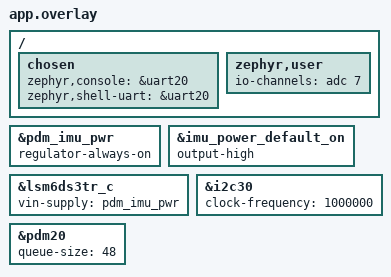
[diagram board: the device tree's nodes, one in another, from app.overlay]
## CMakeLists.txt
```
# SPDX-License-Identifier: Apache-2.0

cmake_minimum_required(VERSION 3.20.0)

set(DTC_OVERLAY_FILE ${CMAKE_CURRENT_SOURCE_DIR}/app.overlay CACHE STRING "" FORCE)

find_package(Zephyr REQUIRED HINTS $ENV{ZEPHYR_BASE})
project(openfloat-serial)

target_sources(app PRIVATE src/main.c src/trace_buffer.c src/trace_store.c src/shot_log.c src/sleep_flush.c src/settings_read.c src/boot_restore.c src/settings_retry.c src/shot_recovery.c)
# The pinned SDK header defines existing Settings/ZMS IDs. Strict boot reads
# preserve errors hidden by the SDK's bulk and single-key Settings loaders.
target_include_directories(app PRIVATE ${ZEPHYR_BASE}/subsys/settings/include)
# Reject undefined shifts, including narrow literals in 128-bit UUID encoders.
target_compile_options(app PRIVATE -Werror=shift-count-overflow)
target_link_libraries(app PRIVATE m)
```

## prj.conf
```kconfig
# Battery-safe default: the XIAO nRF54L15 v1.0 can fail to boot from battery
# when the UART console is enabled. Use prj_uart.conf as an overlay when USB
# serial logs are needed for bench debugging.
CONFIG_SERIAL=n
CONFIG_PRINTK=n
CONFIG_CONSOLE=n
CONFIG_UART_CONSOLE=n
CONFIG_STDOUT_CONSOLE=n
CONFIG_I2C=y
CONFIG_GPIO=y
CONFIG_REGULATOR=y
CONFIG_REGULATOR_FIXED=y
CONFIG_CPU_LOAD=y
CONFIG_ADC=y


# Persistent shot counter: Zephyr Settings on the nRF54L RRAM via ZMS (the
# byte-alterable storage backend for this SoC; Partition Manager allocates the
# settings_storage partition automatically when SETTINGS is enabled).
CONFIG_FLASH=y
CONFIG_FLASH_MAP=y
CONFIG_ZMS=y
# Live acknowledgments save the canonical empty queue; avoid rewriting it.
CONFIG_ZMS_NO_DOUBLE_WRITE=y
CONFIG_SETTINGS=y
CONFIG_SETTINGS_ZMS=y

CONFIG_MAIN_STACK_SIZE=16384
CONFIG_SYSTEM_WORKQUEUE_STACK_SIZE=4096
CONFIG_MPSL_WORK_STACK_SIZE=4096
CONFIG_BT=y
CONFIG_BT_PERIPHERAL=y
CONFIG_BT_DATA_LEN_UPDATE=y
CONFIG_BT_USER_DATA_LEN_UPDATE=y
CONFIG_BT_PHY_UPDATE=y
CONFIG_BT_USER_PHY_UPDATE=y
CONFIG_BT_DEVICE_NAME="OpenFloat-463F"
CONFIG_BT_DEVICE_APPEARANCE=833
CONFIG_BT_CTLR_TX_PWR_PLUS_8=y
CONFIG_BT_MAX_CONN=1
CONFIG_BT_PERIPHERAL_PREF_MIN_INT=6
CONFIG_BT_PERIPHERAL_PREF_MAX_INT=6
CONFIG_BT_PERIPHERAL_PREF_LATENCY=0
CONFIG_BT_PERIPHERAL_PREF_TIMEOUT=400
CONFIG_BT_RX_STACK_SIZE=4096
CONFIG_BT_HCI_TX_STACK_SIZE=2048
CONFIG_BT_LONG_WQ_STACK_SIZE=4096
CONFIG_BT_BUF_CMD_TX_COUNT=2
CONFIG_BT_BUF_ACL_TX_COUNT=6
CONFIG_BT_BUF_ACL_TX_SIZE=217
CONFIG_BT_L2CAP_TX_BUF_COUNT=6
CONFIG_BT_BUF_ACL_RX_SIZE=217
CONFIG_BT_L2CAP_TX_MTU=212

# Deep Sleep / Power Management
CONFIG_POWEROFF=y
CONFIG_REBOOT=y

# Keep 64 KB for ordinary settings, the compact shot log, and four chunked traces.
CONFIG_PM_PARTITION_SIZE_SETTINGS_STORAGE=0x10000

# Audio and PDM microphone drivers
CONFIG_AUDIO=y
CONFIG_AUDIO_DMIC=y
```

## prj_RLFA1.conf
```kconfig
CONFIG_BT_DEVICE_NAME="OpenFloat-RLFA1"
```

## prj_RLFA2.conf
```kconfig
CONFIG_BT_DEVICE_NAME="OpenFloat-RLFA2"
```

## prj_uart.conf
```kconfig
# USB bench/debug overlay. Build with:
#   west build ... -DOVERLAY_CONFIG=prj_uart.conf
#
# Keep the default prj.conf battery-safe for standalone use.
CONFIG_SERIAL=y
CONFIG_PRINTK=y
CONFIG_CONSOLE=y
CONFIG_UART_CONSOLE=y
CONFIG_STDOUT_CONSOLE=y
```

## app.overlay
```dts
&pdm_imu_pwr {
	regulator-always-on;
};

&imu_power_default_on {
	output-high;
};

&lsm6ds3tr_c {
	vin-supply = <&pdm_imu_pwr>;
};

&i2c30 {
	clock-frequency = <1000000>;
};

&pdm20 {
	/* 14-sample blocks arrive at ~1143/s; default queue-size=4 starves PDM. */
	queue-size = <48>;
};

/ {
	chosen {
		zephyr,console = &uart20;
		zephyr,shell-uart = &uart20;
	};

	zephyr,user {
		io-channels = <&adc 7>;
	};
};
```

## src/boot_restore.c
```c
/* SPDX-License-Identifier: Apache-2.0 */
#include "boot_restore.h"
#include <errno.h>
#include <stdio.h>

int boot_restore(const struct boot_restore_io *io)
{
	static const char *const keys[] = {
		"shots", "shotlog", "wakesens", "sleeptime", "sleepsens", "bufrate",
		"bufnvs", "autosleep", "streamrate", "followms", "cant_offset", "pitch_offset",
	};
	int result = 0;
	for (unsigned int attempt = 0; attempt < BOOT_RESTORE_ATTEMPTS; attempt++) {
		result = io->initialize(io->context);
		if (!result) {
			io->reset(io->context);
			for (unsigned int i = 0; i < sizeof(keys) / sizeof(keys[0]); i++) {
				int rc = io->restore_setting(io->context, keys[i]);
				if (i >= 2 && (rc == -EBADMSG || rc == -EMSGSIZE)) continue;
				if (rc && !result) result = rc;
			}
			for (unsigned int slot = 0; slot < 10; slot++) {
				char key[4];
				snprintf(key, sizeof(key), "t%u", slot);
				int rc = io->restore_setting(io->context, key);
				if (rc == -EBADMSG || rc == -EMSGSIZE) continue;
				if (rc && !result) result = rc;
			}
			int rc = io->restore_traces(io->context);
			if (rc && !result) result = rc;
		}
		if (!result) result = io->commit_recovered(io->context);
		if (!result) return 0;
		if (attempt + 1 < BOOT_RESTORE_ATTEMPTS) io->retry_delay(io->context, BOOT_RESTORE_RETRY_DELAY_MS);
	}
	return result;
}
```

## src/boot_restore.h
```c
/* SPDX-License-Identifier: Apache-2.0 */
#ifndef OPENFLOAT_BOOT_RESTORE_H
#define OPENFLOAT_BOOT_RESTORE_H

#include <stdint.h>

#define BOOT_RESTORE_ATTEMPTS 3
#define BOOT_RESTORE_RETRY_DELAY_MS 1000

struct boot_restore_io {
	void *context;
	int (*initialize)(void *context);
	/* Reset RAM to startup defaults, including any partial prior restoration. */
	void (*reset)(void *context);
	/* Relative OpenFloat key. Zero means applied or absent; -EBADMSG/-EMSGSIZE
	 * means malformed. Other errors must propagate without being called absent. */
	int (*restore_setting)(void *context, const char *key);
	int (*restore_traces)(void *context);
	/* Called only after every read/restore succeeds. Persist a recovered capture
	 * ID before BLE acknowledgments can delete the records that established it.
	 * Fresh defaults and unchanged counters need no application writes. */
	int (*commit_recovered)(void *context);
	void (*retry_delay)(void *context, uint32_t milliseconds);
};

/* Run before BLE, acquisition, or application persistence. Malformed counters
 * or shot queues prevent startup; malformed tuning/legacy traces retain defaults.
 * A failure after three passes means the caller must keep startup closed and
 * may retry later. commit_recovered cannot run after any failed read/restore.
 */
int boot_restore(const struct boot_restore_io *io);

#endif
```

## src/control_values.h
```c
/* SPDX-License-Identifier: Apache-2.0 */
#ifndef OPENFLOAT_CONTROL_VALUES_H
#define OPENFLOAT_CONTROL_VALUES_H

#include <errno.h>
#include <math.h>
#include <stdbool.h>
#include <stdint.h>
#include <stdlib.h>
#include <string.h>

/* Parse the complete value before changing device state. strtoul alone accepts
 * negative IDs on the 32-bit target, while atoi treats malformed toggles as 0.
 * Failed conversions leave the caller's value unchanged.
 */
static inline bool openfloat_parse_u32(const char *text, uint32_t *value)
{
	if (*text < '0' || *text > '9') return false;
	char *end;
	errno = 0;
	unsigned long parsed = strtoul(text, &end, 10);
	if (errno || *end || parsed > UINT32_MAX) return false;
	*value = (uint32_t)parsed;
	return true;
}

/* Signed decimal values retain the documented lower/upper clamps for timeout
 * and follow-through commands. Whitespace, suffixes, and overflow are errors.
 */
static inline bool openfloat_parse_i32(const char *text, int32_t *value)
{
	const char *digits = text;
	if (*digits == '-' || *digits == '+') digits++;
	if (*digits < '0' || *digits > '9') return false;
	char *end;
	errno = 0;
	long parsed = strtol(text, &end, 10);
	if (errno || *end || parsed < INT32_MIN || parsed > INT32_MAX) return false;
	*value = (int32_t)parsed;
	return true;
}

/* Accept decimal fractions and exponents, but never NaN, infinity, hexadecimal
 * notation, whitespace, or a partially parsed value. Range errors are rejected
 * before a clamp or float-to-integer conversion can run.
 */
static inline bool openfloat_parse_float(const char *text, float *value)
{
	for (const char *p = text; *p; p++) {
		if ((*p < '0' || *p > '9') && *p != '.' && *p != 'e' && *p != 'E' &&
		    *p != '+' && *p != '-') return false;
	}
	char *end;
	errno = 0;
	float parsed = strtof(text, &end);
	if (errno || end == text || *end || !isfinite(parsed)) return false;
	*value = parsed;
	return true;
}

static inline bool openfloat_valid_buffer_rate(uint32_t value)
{
	return value == 0 || value == 52 || value == 104 || value == 208;
}

static inline bool openfloat_valid_stream_divider(uint32_t value)
{
	return value == 1 || value == 2 || value == 5 || value == 10 || value == 20;
}

/* Persisted values use milli-g and milliseconds. Reject corrupt or older
 * invalid values on restore so the initialized defaults remain in effect.
 */
static inline bool openfloat_valid_tuning_setting(const char *name, uint32_t value)
{
	if (!strcmp(name, "wakesens")) return value >= 500 && value <= 8000;
	if (!strcmp(name, "sleeptime")) return value >= 5000 && value <= 600000;
	if (!strcmp(name, "sleepsens")) return value >= 50 && value <= 500;
	if (!strcmp(name, "bufrate")) return openfloat_valid_buffer_rate(value);
	if (!strcmp(name, "bufnvs") || !strcmp(name, "autosleep")) return value <= 1;
	if (!strcmp(name, "streamrate")) return openfloat_valid_stream_divider(value);
	if (!strcmp(name, "followms")) return value <= 3000;
	return false;
}

#endif
```

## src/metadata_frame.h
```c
/* SPDX-License-Identifier: Apache-2.0 */
#ifndef OPENFLOAT_METADATA_FRAME_H
#define OPENFLOAT_METADATA_FRAME_H

#include <stdint.h>

/* Type 2/3 v2: retain the 29-byte envelope and release sequence at 26.
 * Former reserved timing words at 22/24 carry the upper counter halves.
 */
static inline void openfloat_write_shot_counters(uint8_t frame[29],
					       uint32_t count, uint32_t shot_id)
{
	frame[2] = 2;
	frame[4] = (uint8_t)count;
	frame[5] = (uint8_t)(count >> 8);
	frame[6] = (uint8_t)shot_id;
	frame[7] = (uint8_t)(shot_id >> 8);
	frame[22] = (uint8_t)(shot_id >> 16);
	frame[23] = (uint8_t)(shot_id >> 24);
	frame[24] = (uint8_t)(count >> 16);
	frame[25] = (uint8_t)(count >> 24);
}

/* Type 5 v2: the former reserved word at 18 extends the lifetime count. */
static inline void openfloat_write_storage_count(uint8_t frame[29], uint32_t count)
{
	frame[2] = 2;
	frame[4] = (uint8_t)count;
	frame[5] = (uint8_t)(count >> 8);
	frame[18] = (uint8_t)(count >> 16);
	frame[19] = (uint8_t)(count >> 24);
}

#endif
```

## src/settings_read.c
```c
/* SPDX-License-Identifier: Apache-2.0 */
#include "settings_read.h"
#include <errno.h>
#include <string.h>
#include <zephyr/sys/hash_function.h>
#include "settings/settings_zms.h"

#if !defined(CONFIG_SETTINGS_ZMS) || defined(CONFIG_SETTINGS_ZMS_LEGACY)
#error "Strict Settings reads require the configured non-legacy ZMS backend"
#endif

int openfloat_settings_read(struct zms_fs *fs, const char *key, void *data, size_t capacity)
{
	if (!fs || !fs->ready) return -EACCES;
	size_t length = strlen(key);
	if (!length || length >= SETTINGS_FULL_NAME_LEN) return -EINVAL;
	uint32_t hash = sys_hash32(key, length) & ZMS_HASH_MASK;
	for (unsigned int collision = 0; collision <= ZMS_MAX_COLLISIONS; collision++) {
		uint32_t name_id = ZMS_NAME_ID_FROM_HASH(ZMS_UPDATE_COLLISION_NUM(hash, collision));
		ssize_t rc = zms_get_data_length(fs, name_id);
		if (rc == -ENOENT) continue;
		if (rc < 0) return (int)rc;
		if ((size_t)rc != length) continue;
		char name[SETTINGS_FULL_NAME_LEN];
		rc = zms_read(fs, name_id, name, length);
		if (rc < 0) return (int)rc;
		if ((size_t)rc != length) return -EBADMSG;
		if (memcmp(name, key, length)) continue;
		uint32_t value_id = ZMS_DATA_ID_FROM_NAME(name_id);
		rc = zms_get_data_length(fs, value_id);
		if (rc == -ENOENT || rc == 0) return -EBADMSG;
		if (rc < 0) return (int)rc;
		if ((size_t)rc > capacity) return -EMSGSIZE;
		size_t size = (size_t)rc;
		rc = zms_read(fs, value_id, data, size);
		return rc < 0 ? (int)rc : ((size_t)rc == size ? (int)rc : -EBADMSG);
	}
	return 0;
}
```

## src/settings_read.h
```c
/* SPDX-License-Identifier: Apache-2.0 */
#ifndef OPENFLOAT_SETTINGS_READ_H
#define OPENFLOAT_SETTINGS_READ_H

#include <stddef.h>
struct zms_fs;

/* Boot-only read of an existing Settings/ZMS key. Unlike the SDK's name lookup,
 * preserve storage errors instead of treating them as absent settings. Returns
 * the exact value length, zero for a missing key, or a negative error. A name
 * whose value is missing is malformed, rather than a fresh-device default.
 * Oversized values return -EMSGSIZE without reading into the destination.
 * The caller initializes Settings and serializes against all Settings writers.
 */
int openfloat_settings_read(struct zms_fs *fs, const char *key, void *data, size_t capacity);

#endif
```

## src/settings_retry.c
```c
/* SPDX-License-Identifier: Apache-2.0 */
#include "settings_retry.h"
#include "sleep_flush.h"

void settings_retry_request(struct settings_retry *queue, uint32_t mask, uint32_t now_ms)
{
	mask &= SETTINGS_ALL;
	queue->pending_mask |= mask;
	queue->failed_mask &= ~mask;
	for (unsigned int key = 0; key < SETTING_COUNT; key++) {
		if (!(mask & (UINT32_C(1) << key))) continue;
		queue->token[key]++;
		queue->attempts[key] = 0;
		queue->due_ms[key] = now_ms;
	}
}

int settings_retry_take(struct settings_retry *queue, uint32_t now_ms, uint32_t *token)
{
	for (unsigned int i = 0; i < SETTING_COUNT; i++) {
		unsigned int key = (queue->next_key + i) % SETTING_COUNT;
		uint32_t bit = UINT32_C(1) << key;
		if (!(queue->pending_mask & bit) || (int32_t)(now_ms - queue->due_ms[key]) < 0) continue;
		queue->pending_mask &= ~bit;
		queue->attempts[key]++;
		queue->next_key = (key + 1) % SETTING_COUNT;
		*token = queue->token[key];
		return (int)key;
	}
	return -1;
}

void settings_retry_finish(struct settings_retry *queue, enum openfloat_setting key,
			   uint32_t token, int result, uint32_t now_ms)
{
	if (queue->token[key] != token) return;
	uint32_t bit = UINT32_C(1) << key;
	if (!result) {
		queue->failed_mask &= ~bit;
	} else {
		queue->failed_mask |= bit;
		if (queue->attempts[key] < SETTINGS_RETRY_ATTEMPTS) {
			queue->pending_mask |= bit;
			queue->due_ms[key] = now_ms + SETTINGS_RETRY_DELAY_MS;
		}
	}
}

uint32_t settings_retry_delay(const struct settings_retry *queue, uint32_t now_ms)
{
	uint32_t delay = UINT32_MAX;
	for (unsigned int key = 0; key < SETTING_COUNT; key++) {
		if (!(queue->pending_mask & (UINT32_C(1) << key))) continue;
		int32_t remaining = (int32_t)(queue->due_ms[key] - now_ms);
		if (remaining <= 0) return 0;
		if ((uint32_t)remaining < delay) delay = (uint32_t)remaining;
	}
	return delay;
}

void settings_retry_settle(struct settings_retry *queue, enum openfloat_setting key, int result)
{
	uint32_t bit = UINT32_C(1) << key;
	queue->pending_mask &= ~bit;
	if (result) queue->failed_mask |= bit;
	else queue->failed_mask &= ~bit;
}

const char *settings_retry_key(enum openfloat_setting key)
{
	static const char *const names[] = {
		"openfloat/shots", "openfloat/shotlog", "openfloat/wakesens", "openfloat/sleeptime",
		"openfloat/sleepsens", "openfloat/bufrate", "openfloat/bufnvs", "openfloat/autosleep",
		"openfloat/streamrate", "openfloat/followms", "openfloat/cant_offset", "openfloat/pitch_offset",
	};
	_Static_assert(sizeof(names) / sizeof(names[0]) == SETTING_COUNT, "Settings key list changed");
	return names[key];
}

int settings_retry_save(enum openfloat_setting key, const struct sleep_flush_values *values,
			int (*write)(void *context, const char *key, const void *data, size_t size), void *context)
{
	const void *const data[] = {
		&values->counters, values->queue, &values->wakesens, &values->sleeptime,
		&values->sleepsens, &values->bufrate, &values->bufnvs, &values->autosleep,
		&values->streamrate, &values->followms, &values->cant_offset, &values->pitch_offset,
	};
	_Static_assert(sizeof(data) / sizeof(data[0]) == SETTING_COUNT, "Settings value list changed");
	size_t size = key == SETTING_SHOTS ? sizeof(values->counters) :
		(key == SETTING_SHOTLOG ? sizeof(*values->queue) : sizeof(uint32_t));
	return write(context, settings_retry_key(key), data[key], size);
}
```

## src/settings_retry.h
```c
/* SPDX-License-Identifier: Apache-2.0 */
#ifndef OPENFLOAT_SETTINGS_RETRY_H
#define OPENFLOAT_SETTINGS_RETRY_H

#include <stddef.h>
#include <stdint.h>

enum openfloat_setting {
	SETTING_SHOTS, SETTING_SHOTLOG, SETTING_WAKESENS, SETTING_SLEEPTIME,
	SETTING_SLEEPSENS, SETTING_BUFRATE, SETTING_BUFNVS, SETTING_AUTOSLEEP,
	SETTING_STREAMRATE, SETTING_FOLLOWMS, SETTING_CANT_OFFSET, SETTING_PITCH_OFFSET,
	SETTING_COUNT,
};
#define SETTINGS_ALL ((UINT32_C(1) << SETTING_COUNT) - 1)
#define SETTINGS_RETRY_DELAY_MS 1000
#define SETTINGS_RETRY_ATTEMPTS 3

/* Caller serializes queue operations. Each new value gets a fresh token and
 * budget; obsolete I/O results cannot clear/retry its replacement. Deadlines
 * use wrapping milliseconds, with intervals always below INT32_MAX.
 */
struct settings_retry {
	uint32_t pending_mask, failed_mask;
	uint32_t token[SETTING_COUNT], due_ms[SETTING_COUNT];
	uint8_t attempts[SETTING_COUNT], next_key;
};

void settings_retry_request(struct settings_retry *queue, uint32_t mask, uint32_t now_ms);
/* Returns a ready key or -1. Ready keys rotate so one busy key cannot starve
 * the others. Failed keys wait their own deadline even after unrelated updates.
 */
int settings_retry_take(struct settings_retry *queue, uint32_t now_ms, uint32_t *token);
void settings_retry_finish(struct settings_retry *queue, enum openfloat_setting key,
			   uint32_t token, int result, uint32_t now_ms);
/* Zero if some key is ready, UINT32_MAX if none are pending, else next delay. */
uint32_t settings_retry_delay(const struct settings_retry *queue, uint32_t now_ms);
/* Only after sealing updates and draining I/O: account for a final sleep write.
 * A failed final batch remains unsaved without starting another immediate loop.
 */
void settings_retry_settle(struct settings_retry *queue, enum openfloat_setting key, int result);

const char *settings_retry_key(enum openfloat_setting key);
struct sleep_flush_values;
/* The existing twelve Settings layouts, shared by ordinary saves and sleep. */
int settings_retry_save(enum openfloat_setting key, const struct sleep_flush_values *values,
			int (*write)(void *context, const char *key, const void *data, size_t size), void *context);

#endif
```

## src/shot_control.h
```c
/* SPDX-License-Identifier: Apache-2.0 */
#ifndef OPENFLOAT_SHOT_CONTROL_H
#define OPENFLOAT_SHOT_CONTROL_H

#include <stdbool.h>
#include <stdint.h>
#include <string.h>

struct openfloat_shot_counters {
	uint32_t count;
	uint32_t shot_id;
};

_Static_assert(sizeof(struct openfloat_shot_counters) == 8, "Shot counter settings layout changed");

/* Existing four-byte settings used the lifetime count as the capture ID. New
 * settings save both fields in one value so corrections cannot rewind IDs on
 * reboot. Invalid layouts leave the current counters unchanged.
 */
static inline bool openfloat_restore_shot_counters(struct openfloat_shot_counters *counters,
						  const uint8_t *bytes, size_t size)
{
	if (size != sizeof(uint32_t) && size != sizeof(*counters)) return false;
	struct openfloat_shot_counters restored;
	memcpy(&restored.count, bytes, sizeof(restored.count));
	if (size == sizeof(uint32_t)) restored.shot_id = restored.count;
	else memcpy(&restored.shot_id, bytes + sizeof(restored.count), sizeof(restored.shot_id));
	*counters = restored;
	return true;
}

static inline void openfloat_set_shot_count(struct openfloat_shot_counters *counters, uint32_t count)
{
	counters->count = count;
}

/* Count corrections and resets preserve IDs. The lifetime count saturates at
 * its limit, while capture IDs retain their existing unsigned wrap behavior.
 */
static inline void openfloat_advance_shot(struct openfloat_shot_counters *counters)
{
	if (counters->count < UINT32_MAX) counters->count++;
	counters->shot_id++;
}

#endif
```

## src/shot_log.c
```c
/* SPDX-License-Identifier: Apache-2.0 */
#include "shot_log.h"
#include <string.h>

static uint16_t read16(const uint8_t *p)
{
	return (uint16_t)p[0] | ((uint16_t)p[1] << 8);
}

static uint32_t read32(const uint8_t *p)
{
	return read16(p) | ((uint32_t)read16(p + 2) << 16);
}

static void write16(uint8_t *p, uint16_t value)
{
	p[0] = (uint8_t)value;
	p[1] = (uint8_t)(value >> 8);
}

bool shot_log_valid_storage_size(size_t size)
{
	return size == sizeof(struct stored_shot_log) || size == SHOT_LOG_LEGACY_TIMED_SIZE ||
		size == SHOT_LOG_LEGACY_SIZE;
}

bool shot_log_restore(struct stored_shot_log *dest, const uint8_t *bytes,
		      size_t size, size_t bytes_read)
{
	if (!shot_log_valid_storage_size(size) || bytes_read != size) return false;
	uint16_t count = read16(bytes);
	if (count > STORED_SHOT_CAPACITY) return false;
	bool current = size == sizeof(*dest);
	size_t stride = current ? sizeof(struct stored_shot) :
		(size == SHOT_LOG_LEGACY_TIMED_SIZE ? 22 : 18);
	size_t values = current ? 8 : 4;
	/* Length and count are checked before any mutation. All three formats are
	 * little-endian, so no packed or potentially unaligned struct casts are used.
	 */
	struct stored_shot_log restored;
	memset(&restored, 0, sizeof(restored));
	restored.count = count;
	for (uint16_t i = 0; i < count; i++) {
		const uint8_t *p = bytes + (current ? 4 : 2) + i * stride;
		struct stored_shot *shot = &restored.shots[i];
		shot->shot_count = read16(p);
		shot->shot_id = current ? read32(p + 4) : read16(p + 2);
		shot->ax_mg = (int16_t)read16(p + values);
		shot->ay_mg = (int16_t)read16(p + values + 2);
		shot->az_mg = (int16_t)read16(p + values + 4);
		shot->threshold_cg = read16(p + values + 6);
		shot->roll_cdeg = (int16_t)read16(p + values + 8);
		shot->pitch_cdeg = (int16_t)read16(p + values + 10);
		shot->yaw_cdeg = (int16_t)read16(p + values + 12);
		shot->clicker_dt_ms = stride == 18 ? 0 : read16(p + values + 14);
		shot->impact_dt_ms = stride == 18 ? 0 : read16(p + values + 16);
	}
	memcpy(dest, &restored, sizeof(*dest));
	return true;
}

void shot_log_reset(struct stored_shot_log *log)
{
	memset(log, 0, sizeof(*log));
}

bool shot_log_append(struct stored_shot_log *log, const struct stored_shot *shot)
{
	/* Copy before eviction so a record already in this log can be appended. */
	struct stored_shot copy;
	memcpy(&copy, shot, sizeof(copy));
	memset((uint8_t *)&copy + 2, 0, 2);
	memset((uint8_t *)&copy + 26, 0, 2);
	bool evicted = log->count >= STORED_SHOT_CAPACITY;
	if (evicted) {
		memmove(&log->shots[0], &log->shots[1],
			(STORED_SHOT_CAPACITY - 1) * sizeof(log->shots[0]));
		log->count = STORED_SHOT_CAPACITY - 1;
	}
	memcpy(&log->shots[log->count++], &copy, sizeof(copy));
	return evicted;
}

bool shot_log_remove(struct stored_shot_log *log, uint32_t shot_id)
{
	for (uint16_t i = 0; i < log->count; i++) {
		if (log->shots[i].shot_id != shot_id) continue;
		memmove(&log->shots[i], &log->shots[i + 1],
			(log->count - i - 1) * sizeof(log->shots[0]));
		memset(&log->shots[--log->count], 0, sizeof(log->shots[0]));
		return true;
	}
	return false;
}

void shot_log_build_frame(const struct stored_shot *shot, uint8_t frame[STORED_SHOT_FRAME_SIZE])
{
	memset(frame, 0, STORED_SHOT_FRAME_SIZE);
	frame[0] = 'O'; frame[1] = 'F'; frame[2] = 1; frame[3] = 4;
	write16(frame + 4, shot->shot_count);
	write16(frame + 6, (uint16_t)shot->shot_id);
	write16(frame + 8, (uint16_t)shot->ax_mg);
	write16(frame + 10, (uint16_t)shot->ay_mg);
	write16(frame + 12, (uint16_t)shot->az_mg);
	write16(frame + 14, shot->threshold_cg);
	write16(frame + 16, (uint16_t)shot->roll_cdeg);
	write16(frame + 18, (uint16_t)shot->pitch_cdeg);
	write16(frame + 20, (uint16_t)shot->yaw_cdeg);
	write16(frame + 22, shot->clicker_dt_ms);
	write16(frame + 24, shot->impact_dt_ms);
	write16(frame + 26, (uint16_t)(shot->shot_id >> 16));
}
```

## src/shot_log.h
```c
/* SPDX-License-Identifier: Apache-2.0 */
#ifndef OPENFLOAT_SHOT_LOG_H
#define OPENFLOAT_SHOT_LOG_H

#include <stdbool.h>
#include <stddef.h>
#include <stdint.h>

#define STORED_SHOT_CAPACITY 100
#define SHOT_LOG_LEGACY_TIMED_SIZE (2 + 22 * STORED_SHOT_CAPACITY)
#define SHOT_LOG_LEGACY_SIZE (2 + 18 * STORED_SHOT_CAPACITY)
#define STORED_SHOT_FRAME_SIZE 29

/* Keep the existing ARM32 Settings layout: padded 28-byte records at offset 4.
 * Older layouts used 16-bit IDs and 22/18-byte records at offset 2.
 */
struct stored_shot {
	uint16_t shot_count;
	uint32_t shot_id;
	int16_t ax_mg;
	int16_t ay_mg;
	int16_t az_mg;
	uint16_t threshold_cg;
	int16_t roll_cdeg;
	int16_t pitch_cdeg;
	int16_t yaw_cdeg;
	uint16_t clicker_dt_ms;
	uint16_t impact_dt_ms;
};

struct stored_shot_log {
	uint16_t count;
	struct stored_shot shots[STORED_SHOT_CAPACITY];
};

_Static_assert(sizeof(struct stored_shot) == 28 && offsetof(struct stored_shot, shot_count) == 0 &&
	       offsetof(struct stored_shot, shot_id) == 4 && offsetof(struct stored_shot, ax_mg) == 8 &&
	       offsetof(struct stored_shot, ay_mg) == 10 && offsetof(struct stored_shot, az_mg) == 12 &&
	       offsetof(struct stored_shot, threshold_cg) == 14 && offsetof(struct stored_shot, roll_cdeg) == 16 &&
	       offsetof(struct stored_shot, pitch_cdeg) == 18 && offsetof(struct stored_shot, yaw_cdeg) == 20 &&
	       offsetof(struct stored_shot, clicker_dt_ms) == 22 && offsetof(struct stored_shot, impact_dt_ms) == 24,
	       "Stored shot Settings layout changed");
_Static_assert(sizeof(struct stored_shot_log) == 2804 && offsetof(struct stored_shot_log, count) == 0 &&
	       offsetof(struct stored_shot_log, shots) == 4,
	       "Shot log Settings layout changed");

bool shot_log_valid_storage_size(size_t size);
/* Validate the declared Settings size and actual read result separately. A short
 * read cannot masquerade as a complete smaller legacy layout. Rejected bytes
 * leave dest unchanged; successful restores clear unused records and padding.
 */
bool shot_log_restore(struct stored_shot_log *dest, const uint8_t *bytes,
		      size_t size, size_t bytes_read);
/* Start from a zeroed/reset or successfully restored log. Mutations retain
 * zero padding and unused slots, making every empty queue byte-identical.
 * Callers provide locking. Append returns true if the oldest record was evicted;
 * remove matches the complete capture ID and leaves unknown IDs unchanged.
 */
void shot_log_reset(struct stored_shot_log *log);
bool shot_log_append(struct stored_shot_log *log, const struct stored_shot *shot);
bool shot_log_remove(struct stored_shot_log *log, uint32_t shot_id);
void shot_log_build_frame(const struct stored_shot *shot, uint8_t frame[STORED_SHOT_FRAME_SIZE]);

#endif
```

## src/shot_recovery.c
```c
/* SPDX-License-Identifier: Apache-2.0 */
#include "shot_recovery.h"
#include <errno.h>

static bool include_id(uint32_t *latest, bool *present, uint32_t id)
{
	if (!*present) {
		*latest = id;
		*present = true;
		return true;
	}
	uint32_t distance = id - *latest;
	if (distance == UINT32_C(0x80000000)) return false;
	if (distance && distance < UINT32_C(0x80000000)) *latest = id;
	return true;
}

int shot_recover_id(struct openfloat_shot_counters *counters, bool counter_present,
		    const struct stored_shot_log *log, bool full_log_ids,
		    const struct stored_trace *traces, size_t trace_slots)
{
	uint32_t latest = counters->shot_id;
	if (full_log_ids) {
		for (unsigned int i = 0; i < log->count; i++) {
			if (!include_id(&latest, &counter_present, log->shots[i].shot_id)) return -EBADMSG;
		}
	}
	for (size_t i = 0; i < trace_slots; i++) {
		if (traces[i].count && !include_id(&latest, &counter_present, traces[i].shot_id)) return -EBADMSG;
	}
	counters->shot_id = latest;
	return 0;
}
```
